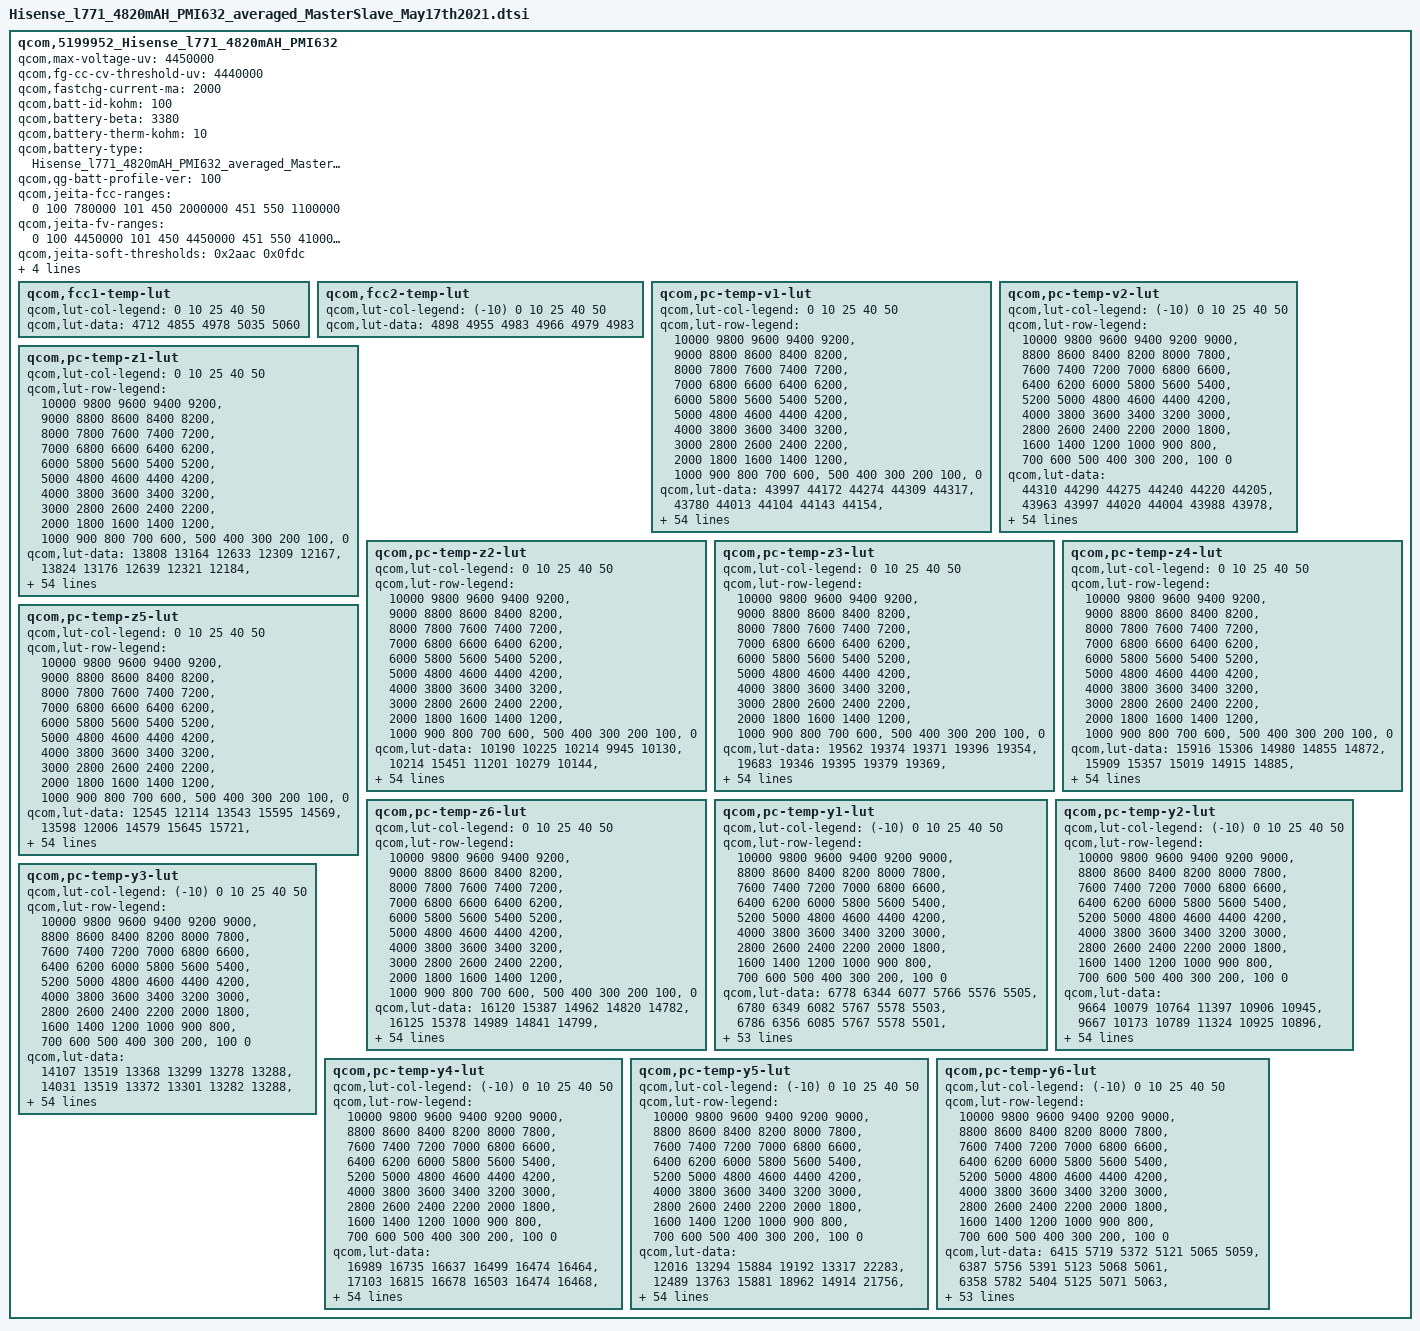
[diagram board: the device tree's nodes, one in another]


qcom,5199952_Hisense_l771_4820mAH_PMI632 {
    /* 5199952_Hisense_l771_4820mAH_PMI632_averaged_MasterSlave_May17th2021 */
    qcom,max-voltage-uv = <4450000>;
    qcom,fg-cc-cv-threshold-uv = <4440000>;
    qcom,fastchg-current-ma = <2000>;
    qcom,batt-id-kohm = <100>;
    qcom,battery-beta = <3380>;
    qcom,battery-therm-kohm = <10>;
    qcom,battery-type = "Hisense_l771_4820mAH_PMI632_averaged_MasterSlave_May17th2021";
    qcom,qg-batt-profile-ver = <100>;

	qcom,jeita-fcc-ranges = <0  100  780000
				101 450  2000000
				451 550  1100000>;

	qcom,jeita-fv-ranges =  <0  100  4450000
				 101 450  4450000
				 451 550  4100000>;
	/* COOL = 10 DegC, WARM = 45 DegC */
	qcom,jeita-soft-thresholds = <0x2aac 0x0fdc>;
	/* COLD = 0 DegC, HOT = 53 DegC */
	qcom,jeita-hard-thresholds = <0x36b9 0x0ca0>;
	/* COOL hys = 13 degC, WARM hys = 42 degC */
	qcom,jeita-soft-hys-thresholds = <0x2767 0x1149>;
	qcom,jeita-soft-fcc-ua = <780000 1100000>;
	qcom,jeita-soft-fv-uv = <4450000 4100000>;

	qcom,fcc1-temp-lut {
		qcom,lut-col-legend = <0 10 25 40 50>;
		qcom,lut-data = <4712 4855 4978 5035 5060>;
	};

	qcom,fcc2-temp-lut {
		qcom,lut-col-legend = <(-10) 0 10 25 40 50>;
		qcom,lut-data = <4898 4955 4983 4966 4979 4983>;
	};

	qcom,pc-temp-v1-lut {
		qcom,lut-col-legend = <0 10 25 40 50>;
		qcom,lut-row-legend = <10000 9800 9600 9400 9200>,
			<9000 8800 8600 8400 8200>,
			<8000 7800 7600 7400 7200>,
			<7000 6800 6600 6400 6200>,
			<6000 5800 5600 5400 5200>,
			<5000 4800 4600 4400 4200>,
			<4000 3800 3600 3400 3200>,
			<3000 2800 2600 2400 2200>,
			<2000 1800 1600 1400 1200>,
			<1000 900 800 700 600>,
			<500 400 300 200 100>,
			<0>;
		qcom,lut-data = <43997 44172 44274 44309 44317>,
			<43780 44013 44104 44143 44154>,
			<43555 43788 43926 43973 43987>,
			<43324 43555 43735 43781 43801>,
			<43090 43328 43529 43577 43601>,
			<42850 43095 43297 43361 43389>,
			<42606 42855 43049 43131 43163>,
			<42367 42610 42803 42893 42926>,
			<42129 42365 42557 42651 42685>,
			<41895 42123 42311 42404 42436>,
			<41668 41884 42067 42159 42190>,
			<41447 41651 41826 41915 41945>,
			<41227 41422 41590 41675 41704>,
			<41009 41200 41357 41438 41466>,
			<40796 40982 41135 41208 41234>,
			<40592 40771 40926 40984 41011>,
			<40395 40566 40721 40767 40795>,
			<40207 40368 40515 40563 40588>,
			<40027 40178 40313 40375 40390>,
			<39855 39999 40117 40181 40192>,
			<39695 39822 39935 39975 39987>,
			<39545 39638 39728 39758 39776>,
			<39397 39451 39422 39509 39544>,
			<39250 39247 39114 39238 39285>,
			<39104 38998 38962 39050 39088>,
			<38956 38785 38873 38936 38964>,
			<38802 38673 38787 38837 38860>,
			<38671 38595 38693 38732 38751>,
			<38570 38523 38602 38633 38646>,
			<38486 38457 38516 38537 38543>,
			<38420 38397 38437 38446 38442>,
			<38368 38342 38363 38360 38349>,
			<38323 38291 38297 38282 38269>,
			<38283 38244 38234 38207 38195>,
			<38247 38202 38176 38135 38120>,
			<38210 38160 38120 38065 38047>,
			<38174 38116 38063 37999 37974>,
			<38133 38070 38008 37939 37903>,
			<38072 38007 37941 37870 37824>,
			<37988 37915 37847 37772 37719>,
			<37888 37807 37735 37653 37593>,
			<37762 37682 37614 37529 37464>,
			<37619 37539 37478 37396 37330>,
			<37454 37377 37323 37246 37183>,
			<37327 37237 37179 37110 37050>,
			<37223 37148 37087 37024 36973>,
			<37173 37121 37058 36996 36941>,
			<37139 37088 37039 36975 36919>,
			<37100 37058 37014 36953 36894>,
			<37041 36996 36952 36886 36817>,
			<36847 36752 36709 36622 36532>,
			<36405 36301 36269 36178 36080>,
			<35825 35705 35686 35596 35505>,
			<35031 34882 34891 34809 34718>,
			<33700 33497 33660 33599 33502>,
			<30000 30000 30000 30000 30000>;
	};

	qcom,pc-temp-v2-lut {
		qcom,lut-col-legend = <(-10) 0 10 25 40 50>;
		qcom,lut-row-legend = <10000 9800 9600 9400 9200 9000>,
			<8800 8600 8400 8200 8000 7800>,
			<7600 7400 7200 7000 6800 6600>,
			<6400 6200 6000 5800 5600 5400>,
			<5200 5000 4800 4600 4400 4200>,
			<4000 3800 3600 3400 3200 3000>,
			<2800 2600 2400 2200 2000 1800>,
			<1600 1400 1200 1000 900 800>,
			<700 600 500 400 300 200>,
			<100 0>;
		qcom,lut-data = <44310 44290 44275 44240 44220 44205>,
			<43963 43997 44020 44004 43988 43978>,
			<43643 43726 43776 43773 43762 43755>,
			<43352 43482 43546 43551 43546 43538>,
			<43089 43263 43329 43337 43337 43328>,
			<42835 43036 43102 43114 43120 43111>,
			<42586 42791 42860 42878 42887 42880>,
			<42344 42539 42611 42635 42646 42642>,
			<42099 42286 42361 42391 42404 42401>,
			<41853 42030 42108 42144 42157 42155>,
			<41611 41779 41860 41901 41914 41912>,
			<41372 41531 41617 41660 41673 41671>,
			<41139 41295 41380 41424 41436 41433>,
			<40920 41089 41152 41194 41203 41200>,
			<40711 40897 40932 40969 40976 40974>,
			<40468 40684 40724 40751 40757 40755>,
			<40147 40449 40529 40538 40546 40545>,
			<39829 40199 40314 40333 40342 40341>,
			<39590 39928 40043 40148 40155 40153>,
			<39386 39651 39758 39962 39964 39962>,
			<39187 39396 39513 39725 39729 39729>,
			<38985 39156 39290 39433 39454 39460>,
			<38798 38941 39091 39185 39217 39228>,
			<38630 38755 38913 38997 39027 39037>,
			<38478 38587 38753 38837 38863 38872>,
			<38362 38426 38611 38696 38721 38729>,
			<38274 38275 38483 38573 38598 38604>,
			<38196 38168 38357 38459 38485 38488>,
			<38123 38098 38228 38351 38379 38381>,
			<38055 38039 38114 38251 38282 38282>,
			<37988 37980 38017 38162 38198 38195>,
			<37921 37924 37932 38080 38121 38113>,
			<37855 37868 37868 38005 38041 38033>,
			<37786 37812 37817 37937 37959 37953>,
			<37715 37756 37769 37868 37874 37865>,
			<37642 37697 37721 37793 37787 37763>,
			<37566 37635 37670 37715 37696 37656>,
			<37489 37566 37608 37634 37601 37552>,
			<37408 37492 37532 37549 37502 37451>,
			<37327 37409 37446 37463 37406 37353>,
			<37250 37314 37342 37377 37317 37262>,
			<37176 37208 37225 37274 37212 37156>,
			<37110 37089 37090 37139 37081 37031>,
			<37043 36961 36947 37013 36958 36903>,
			<36971 36849 36824 36895 36867 36818>,
			<36882 36761 36735 36843 36826 36779>,
			<36831 36726 36699 36827 36814 36767>,
			<36779 36693 36655 36811 36797 36751>,
			<36717 36646 36585 36778 36765 36715>,
			<36639 36563 36467 36700 36671 36595>,
			<36520 36355 36206 36412 36329 36222>,
			<36304 35919 35747 35919 35824 35711>,
			<35904 35236 35094 35286 35170 35044>,
			<35266 34271 34157 34430 34267 34122>,
			<34215 32940 32742 33163 33019 32859>,
			<33190 29783 27667 27737 27880 27908>;
	};

	qcom,pc-temp-z1-lut {
		qcom,lut-col-legend = <0 10 25 40 50>;
		qcom,lut-row-legend = <10000 9800 9600 9400 9200>,
			<9000 8800 8600 8400 8200>,
			<8000 7800 7600 7400 7200>,
			<7000 6800 6600 6400 6200>,
			<6000 5800 5600 5400 5200>,
			<5000 4800 4600 4400 4200>,
			<4000 3800 3600 3400 3200>,
			<3000 2800 2600 2400 2200>,
			<2000 1800 1600 1400 1200>,
			<1000 900 800 700 600>,
			<500 400 300 200 100>,
			<0>;
		qcom,lut-data = <13808 13164 12633 12309 12167>,
			<13824 13176 12639 12321 12184>,
			<13822 13186 12641 12314 12184>,
			<13804 13190 12641 12312 12179>,
			<13788 13182 12639 12307 12176>,
			<13778 13169 12633 12302 12173>,
			<13768 13156 12622 12296 12170>,
			<13762 13140 12613 12290 12166>,
			<13758 13125 12601 12283 12162>,
			<13756 13112 12589 12277 12158>,
			<13748 13099 12581 12272 12157>,
			<13729 13088 12574 12269 12157>,
			<13716 13080 12569 12266 12156>,
			<13695 13071 12565 12265 12156>,
			<13674 13060 12562 12264 12155>,
			<13660 13050 12562 12263 12155>,
			<13648 13047 12562 12262 12156>,
			<13643 13045 12559 12261 12156>,
			<13648 13044 12555 12261 12155>,
			<13653 13048 12555 12261 12154>,
			<13648 13053 12556 12261 12155>,
			<13633 13054 12557 12260 12155>,
			<13624 13057 12561 12260 12156>,
			<13622 13058 12566 12260 12156>,
			<13621 13066 12568 12260 12157>,
			<13627 13072 12569 12262 12158>,
			<13655 13071 12569 12265 12159>,
			<13675 13067 12572 12268 12162>,
			<13671 13067 12575 12271 12164>,
			<13663 13078 12582 12274 12168>,
			<13661 13088 12591 12278 12172>,
			<13663 13092 12594 12282 12176>,
			<13664 13095 12595 12287 12180>,
			<13659 13098 12596 12293 12184>,
			<13650 13101 12599 12298 12188>,
			<13652 13105 12605 12303 12193>,
			<13676 13115 12612 12308 12198>,
			<13700 13129 12622 12312 12203>,
			<13712 13136 12628 12316 12207>,
			<13729 13138 12632 12321 12211>,
			<13743 13142 12636 12325 12214>,
			<13759 13148 12641 12328 12216>,
			<13773 13158 12647 12332 12219>,
			<13769 13172 12654 12335 12221>,
			<13772 13182 12662 12340 12224>,
			<13762 13193 12665 12344 12226>,
			<13758 13196 12666 12343 12225>,
			<13757 13191 12669 12345 12226>,
			<13786 13177 12679 12349 12229>,
			<13766 13191 12678 12352 12233>,
			<13799 13228 12679 12358 12238>,
			<13823 13227 12694 12369 12244>,
			<13809 13239 12702 12377 12254>,
			<13840 13263 12727 12394 12270>,
			<13840 13263 12727 12394 12270>,
			<13840 13263 12727 12394 12270>;
	};

	qcom,pc-temp-z2-lut {
		qcom,lut-col-legend = <0 10 25 40 50>;
		qcom,lut-row-legend = <10000 9800 9600 9400 9200>,
			<9000 8800 8600 8400 8200>,
			<8000 7800 7600 7400 7200>,
			<7000 6800 6600 6400 6200>,
			<6000 5800 5600 5400 5200>,
			<5000 4800 4600 4400 4200>,
			<4000 3800 3600 3400 3200>,
			<3000 2800 2600 2400 2200>,
			<2000 1800 1600 1400 1200>,
			<1000 900 800 700 600>,
			<500 400 300 200 100>,
			<0>;
		qcom,lut-data = <10190 10225 10214 9945 10130>,
			<10214 15451 11201 10279 10144>,
			<10217 12170 11731 10297 10109>,
			<10211 10433 11796 10327 10208>,
			<10203 10387 11702 10333 10258>,
			<10187 10362 11166 10333 10272>,
			<10167 10333 10525 10322 10247>,
			<10157 10306 10381 10306 10219>,
			<10151 10284 10355 10277 10212>,
			<10148 10264 10335 10240 10208>,
			<10194 10250 10311 10211 10198>,
			<10286 10245 10294 10186 10171>,
			<10306 10244 10288 10179 10157>,
			<10208 10245 10286 10194 10159>,
			<10116 10248 10317 10212 10163>,
			<10108 10253 10711 10218 10167>,
			<10107 10265 11060 10222 10174>,
			<10107 10289 10865 10302 10179>,
			<10112 10311 10457 10749 10182>,
			<10120 10331 10362 11015 10187>,
			<10131 10349 10386 10787 10248>,
			<10146 10365 10409 10466 10343>,
			<10162 10381 10422 10356 10321>,
			<10181 10384 10431 10261 10157>,
			<10201 10364 10419 10202 10078>,
			<10216 10346 10370 10162 10095>,
			<10228 10351 10348 10144 10120>,
			<10238 10366 10365 10163 10137>,
			<10246 10376 10391 10208 10155>,
			<10252 10382 10413 10257 10204>,
			<10260 10388 10434 10337 10367>,
			<10268 10395 10440 10380 10466>,
			<10276 10403 10437 10382 10412>,
			<10285 10412 10436 10378 10311>,
			<10294 10420 10437 10359 10211>,
			<10304 10429 10441 10323 10102>,
			<10314 10438 10448 10312 10070>,
			<10326 10448 10468 10319 10103>,
			<10338 10461 10491 10331 10148>,
			<10353 10478 10525 10380 10179>,
			<10369 10493 10556 10451 10213>,
			<10387 10503 10566 10475 10284>,
			<10414 10513 10571 10488 10409>,
			<10470 10535 10573 10486 10421>,
			<10271 10649 10599 10463 10381>,
			<9638 10791 10662 10363 10247>,
			<9952 10587 10651 10320 10219>,
			<9795 10608 10630 10315 10220>,
			<9590 10626 10626 10351 10263>,
			<9608 10610 10686 10449 10335>,
			<9558 10525 10674 10379 10249>,
			<9647 10389 10546 10197 10055>,
			<9731 10234 10491 10135 9988>,
			<9660 10078 10403 10080 9931>,
			<9660 10078 10403 10080 9931>,
			<9660 10078 10403 10080 9931>;
	};

	qcom,pc-temp-z3-lut {
		qcom,lut-col-legend = <0 10 25 40 50>;
		qcom,lut-row-legend = <10000 9800 9600 9400 9200>,
			<9000 8800 8600 8400 8200>,
			<8000 7800 7600 7400 7200>,
			<7000 6800 6600 6400 6200>,
			<6000 5800 5600 5400 5200>,
			<5000 4800 4600 4400 4200>,
			<4000 3800 3600 3400 3200>,
			<3000 2800 2600 2400 2200>,
			<2000 1800 1600 1400 1200>,
			<1000 900 800 700 600>,
			<500 400 300 200 100>,
			<0>;
		qcom,lut-data = <19562 19374 19371 19396 19354>,
			<19683 19346 19395 19379 19369>,
			<19747 19497 19412 19389 19371>,
			<19789 19585 19429 19415 19403>,
			<19810 19598 19445 19429 19416>,
			<19817 19606 19465 19440 19426>,
			<19822 19611 19487 19451 19435>,
			<19821 19616 19493 19456 19441>,
			<19807 19617 19495 19456 19446>,
			<19797 19614 19496 19456 19450>,
			<19811 19609 19495 19455 19451>,
			<19840 19603 19492 19453 19449>,
			<19846 19595 19488 19450 19447>,
			<19812 19591 19481 19446 19442>,
			<19779 19589 19479 19440 19435>,
			<19772 19587 19490 19435 19428>,
			<19769 19583 19500 19430 19420>,
			<19767 19575 19485 19426 19413>,
			<19766 19569 19456 19424 19406>,
			<19765 19565 19449 19424 19402>,
			<19762 19563 19452 19423 19402>,
			<19758 19567 19456 19420 19402>,
			<19756 19577 19463 19414 19399>,
			<19757 19586 19471 19406 19386>,
			<19758 19594 19468 19396 19374>,
			<19761 19599 19452 19383 19363>,
			<19768 19596 19442 19375 19356>,
			<19771 19589 19439 19376 19359>,
			<19768 19583 19437 19377 19369>,
			<19760 19578 19439 19382 19385>,
			<19752 19574 19444 19397 19418>,
			<19742 19571 19449 19411 19437>,
			<19732 19568 19455 19420 19433>,
			<19722 19567 19458 19426 19425>,
			<19713 19566 19458 19425 19415>,
			<19704 19564 19458 19418 19401>,
			<19695 19562 19457 19410 19390>,
			<19687 19559 19451 19398 19381>,
			<19681 19556 19446 19391 19377>,
			<19677 19552 19445 19391 19375>,
			<19670 19547 19444 19392 19375>,
			<19658 19543 19441 19393 19377>,
			<19641 19537 19437 19395 19388>,
			<19619 19527 19432 19396 19392>,
			<19440 19495 19423 19393 19392>,
			<19286 19436 19405 19372 19365>,
			<19328 19346 19403 19367 19358>,
			<19295 19335 19392 19362 19349>,
			<19279 19308 19389 19352 19341>,
			<19275 19306 19377 19344 19339>,
			<19282 19330 19368 19362 19370>,
			<19314 19331 19359 19384 19391>,
			<19350 19331 19361 19390 19388>,
			<19383 19347 19355 19389 19385>,
			<19383 19347 19355 19389 19385>,
			<19383 19347 19355 19389 19385>;
	};

	qcom,pc-temp-z4-lut {
		qcom,lut-col-legend = <0 10 25 40 50>;
		qcom,lut-row-legend = <10000 9800 9600 9400 9200>,
			<9000 8800 8600 8400 8200>,
			<8000 7800 7600 7400 7200>,
			<7000 6800 6600 6400 6200>,
			<6000 5800 5600 5400 5200>,
			<5000 4800 4600 4400 4200>,
			<4000 3800 3600 3400 3200>,
			<3000 2800 2600 2400 2200>,
			<2000 1800 1600 1400 1200>,
			<1000 900 800 700 600>,
			<500 400 300 200 100>,
			<0>;
		qcom,lut-data = <15916 15306 14980 14855 14872>,
			<15909 15357 15019 14915 14885>,
			<15863 15317 15076 14930 14872>,
			<15697 15264 15019 14935 14912>,
			<15529 15187 14958 14905 14890>,
			<15414 15099 14924 14877 14866>,
			<15313 15033 14897 14849 14844>,
			<15234 14976 14868 14823 14823>,
			<15175 14931 14837 14802 14803>,
			<15115 14896 14810 14784 14784>,
			<15023 14867 14787 14766 14766>,
			<14925 14843 14768 14749 14748>,
			<14899 14823 14753 14735 14735>,
			<14907 14805 14741 14723 14726>,
			<14916 14785 14723 14713 14720>,
			<14908 14769 14684 14708 14715>,
			<14886 14759 14656 14704 14712>,
			<14864 14751 14671 14697 14708>,
			<14846 14745 14703 14678 14703>,
			<14829 14740 14711 14668 14700>,
			<14814 14736 14710 14681 14706>,
			<14801 14737 14710 14708 14723>,
			<14791 14740 14776 14759 14759>,
			<14780 14748 14869 14845 14840>,
			<14773 14803 14879 14873 14876>,
			<14775 14852 14869 14870 14873>,
			<14790 14850 14857 14863 14865>,
			<14802 14837 14843 14852 14852>,
			<14806 14824 14827 14834 14827>,
			<14809 14810 14809 14811 14795>,
			<14809 14797 14789 14779 14745>,
			<14803 14784 14770 14751 14712>,
			<14796 14771 14751 14725 14702>,
			<14788 14760 14736 14706 14696>,
			<14779 14748 14725 14703 14696>,
			<14772 14740 14717 14701 14699>,
			<14765 14735 14716 14701 14700>,
			<14759 14731 14717 14702 14699>,
			<14751 14731 14718 14703 14699>,
			<14743 14733 14723 14710 14708>,
			<14740 14735 14729 14721 14725>,
			<14740 14732 14729 14722 14726>,
			<14740 14726 14726 14718 14715>,
			<14733 14720 14722 14716 14711>,
			<14833 14703 14706 14710 14706>,
			<14962 14703 14677 14686 14687>,
			<14914 14796 14669 14684 14687>,
			<14940 14803 14663 14673 14679>,
			<14954 14824 14653 14661 14660>,
			<14951 14821 14659 14660 14649>,
			<14952 14809 14692 14677 14666>,
			<14945 14827 14716 14678 14675>,
			<14933 14841 14719 14679 14686>,
			<14941 14847 14731 14687 14697>,
			<14941 14847 14731 14687 14697>,
			<14941 14847 14731 14687 14697>;
	};

	qcom,pc-temp-z5-lut {
		qcom,lut-col-legend = <0 10 25 40 50>;
		qcom,lut-row-legend = <10000 9800 9600 9400 9200>,
			<9000 8800 8600 8400 8200>,
			<8000 7800 7600 7400 7200>,
			<7000 6800 6600 6400 6200>,
			<6000 5800 5600 5400 5200>,
			<5000 4800 4600 4400 4200>,
			<4000 3800 3600 3400 3200>,
			<3000 2800 2600 2400 2200>,
			<2000 1800 1600 1400 1200>,
			<1000 900 800 700 600>,
			<500 400 300 200 100>,
			<0>;
		qcom,lut-data = <12545 12114 13543 15595 14569>,
			<13598 12006 14579 15645 15721>,
			<14269 14294 14693 15780 15835>,
			<14736 15811 14695 16919 17167>,
			<15116 16196 14912 17757 18076>,
			<15467 16483 16049 18634 18953>,
			<15764 16939 17690 19566 19825>,
			<15967 17539 18629 20364 20759>,
			<16083 18072 19202 20941 21915>,
			<16249 18498 19804 21477 23241>,
			<17270 18894 20552 22149 24540>,
			<18988 19278 21340 22973 25840>,
			<19457 19653 22026 23956 27047>,
			<18883 20141 22692 25267 28363>,
			<18350 21208 24197 26558 29330>,
			<18527 22473 30523 27546 29339>,
			<19209 23371 35715 28388 29110>,
			<20026 24186 32695 29540 29064>,
			<21075 25046 26397 32769 29632>,
			<22316 25865 25268 34610 30549>,
			<23515 27026 28157 36208 32259>,
			<24743 30529 31754 37621 34212>,
			<26472 37322 36313 35047 33106>,
			<29808 42546 40442 29023 26466>,
			<34285 46665 38603 24191 21214>,
			<39237 49090 29519 20348 18189>,
			<45528 46654 23888 17944 16466>,
			<48791 40059 22042 17185 16442>,
			<47836 35785 21106 16753 16621>,
			<45752 33242 21284 16940 17717>,
			<43611 31794 22059 18452 23832>,
			<40982 31690 23147 20559 28638>,
			<38689 32065 25113 24211 30053>,
			<37151 32748 27505 27859 30855>,
			<35818 34679 30606 29414 30258>,
			<34846 36548 33610 30423 27958>,
			<33621 37642 34055 30418 26550>,
			<32755 38666 33692 28211 25997>,
			<33536 39051 33421 26525 25599>,
			<35641 39172 33300 26815 25190>,
			<36416 39011 33112 27300 24860>,
			<34491 38122 31796 26881 24938>,
			<32245 36759 29039 25180 25700>,
			<30810 35706 28591 25390 27095>,
			<18383 33067 29187 25688 27926>,
			<11845 22713 29511 22719 21175>,
			<12433 13879 29183 21044 19157>,
			<11897 13317 25867 21149 18173>,
			<11634 12425 26277 20669 19039>,
			<11610 12430 22993 19107 20043>,
			<11687 13201 18521 20284 25196>,
			<12080 12902 15843 21117 24818>,
			<12350 12638 15490 20886 20631>,
			<12779 12756 14652 18723 17603>,
			<12779 12756 14652 18723 17603>,
			<12779 12756 14652 18723 17603>;
	};

	qcom,pc-temp-z6-lut {
		qcom,lut-col-legend = <0 10 25 40 50>;
		qcom,lut-row-legend = <10000 9800 9600 9400 9200>,
			<9000 8800 8600 8400 8200>,
			<8000 7800 7600 7400 7200>,
			<7000 6800 6600 6400 6200>,
			<6000 5800 5600 5400 5200>,
			<5000 4800 4600 4400 4200>,
			<4000 3800 3600 3400 3200>,
			<3000 2800 2600 2400 2200>,
			<2000 1800 1600 1400 1200>,
			<1000 900 800 700 600>,
			<500 400 300 200 100>,
			<0>;
		qcom,lut-data = <16120 15387 14962 14820 14782>,
			<16125 15378 14989 14841 14799>,
			<16107 15402 15018 14854 14794>,
			<16016 15413 14997 14863 14824>,
			<15919 15375 14977 14860 14823>,
			<15848 15314 14968 14855 14822>,
			<15783 15271 14960 14847 14817>,
			<15725 15235 14949 14838 14810>,
			<15672 15204 14933 14829 14804>,
			<15625 15177 14917 14819 14798>,
			<15584 15153 14904 14811 14791>,
			<15546 15132 14891 14802 14783>,
			<15517 15113 14880 14794 14776>,
			<15493 15096 14869 14785 14769>,
			<15473 15082 14860 14778 14762>,
			<15455 15069 14851 14773 14756>,
			<15438 15059 14844 14768 14750>,
			<15423 15050 14840 14762 14744>,
			<15408 15044 14837 14753 14738>,
			<15395 15040 14836 14750 14734>,
			<15384 15038 14838 14754 14736>,
			<15374 15040 14840 14762 14743>,
			<15368 15047 14872 14780 14756>,
			<15365 15058 14917 14811 14783>,
			<15363 15087 14920 14821 14794>,
			<15366 15111 14908 14814 14789>,
			<15378 15109 14898 14806 14781>,
			<15386 15102 14891 14800 14776>,
			<15386 15095 14885 14795 14772>,
			<15385 15089 14880 14790 14768>,
			<15383 15082 14875 14785 14765>,
			<15378 15077 14871 14780 14761>,
			<15371 15072 14867 14776 14756>,
			<15364 15068 14863 14772 14750>,
			<15357 15064 14861 14769 14744>,
			<15353 15061 14859 14766 14739>,
			<15352 15062 14858 14762 14734>,
			<15351 15062 14857 14757 14729>,
			<15352 15063 14856 14754 14726>,
			<15356 15067 14859 14757 14729>,
			<15359 15071 14864 14762 14736>,
			<15364 15072 14864 14764 14738>,
			<15366 15072 14863 14764 14740>,
			<15364 15071 14861 14764 14740>,
			<15333 15058 14854 14761 14739>,
			<15316 15035 14836 14741 14716>,
			<15315 15028 14832 14737 14713>,
			<15312 15026 14824 14730 14705>,
			<15312 15023 14818 14719 14692>,
			<15317 15026 14818 14716 14687>,
			<15329 15039 14831 14734 14711>,
			<15349 15054 14841 14749 14730>,
			<15371 15069 14849 14755 14736>,
			<15413 15095 14858 14763 14743>,
			<15413 15095 14858 14763 14743>,
			<15413 15095 14858 14763 14743>;
	};

	qcom,pc-temp-y1-lut {
		qcom,lut-col-legend = <(-10) 0 10 25 40 50>;
		qcom,lut-row-legend = <10000 9800 9600 9400 9200 9000>,
			<8800 8600 8400 8200 8000 7800>,
			<7600 7400 7200 7000 6800 6600>,
			<6400 6200 6000 5800 5600 5400>,
			<5200 5000 4800 4600 4400 4200>,
			<4000 3800 3600 3400 3200 3000>,
			<2800 2600 2400 2200 2000 1800>,
			<1600 1400 1200 1000 900 800>,
			<700 600 500 400 300 200>,
			<100 0>;
		qcom,lut-data = <6778 6344 6077 5766 5576 5505>,
			<6780 6349 6082 5767 5578 5503>,
			<6786 6356 6085 5767 5578 5501>,
			<6795 6363 6086 5767 5578 5499>,
			<6803 6369 6085 5767 5578 5498>,
			<6808 6372 6084 5767 5577 5497>,
			<6820 6383 6075 5767 5575 5497>,
			<6835 6395 6066 5767 5573 5497>,
			<6836 6392 6065 5765 5572 5496>,
			<6833 6380 6065 5760 5570 5495>,
			<6830 6374 6065 5759 5568 5493>,
			<6829 6371 6064 5760 5566 5493>,
			<6826 6369 6064 5762 5564 5492>,
			<6822 6375 6068 5760 5564 5492>,
			<6816 6384 6074 5756 5564 5491>,
			<6818 6386 6075 5755 5563 5491>,
			<6833 6380 6071 5754 5562 5490>,
			<6845 6377 6068 5754 5561 5489>,
			<6837 6388 6074 5754 5561 5489>,
			<6816 6405 6082 5755 5560 5488>,
			<6811 6409 6083 5755 5561 5488>,
			<6829 6401 6080 5755 5561 5488>,
			<6846 6396 6078 5755 5562 5488>,
			<6844 6392 6074 5758 5563 5490>,
			<6837 6387 6069 5763 5565 5491>,
			<6833 6386 6074 5765 5566 5493>,
			<6824 6392 6083 5766 5568 5495>,
			<6816 6393 6085 5767 5570 5496>,
			<6810 6390 6082 5769 5572 5499>,
			<6803 6388 6079 5772 5574 5501>,
			<6802 6386 6079 5777 5577 5503>,
			<6807 6385 6079 5783 5580 5505>,
			<6810 6386 6083 5784 5583 5507>,
			<6813 6390 6093 5783 5586 5509>,
			<6817 6392 6097 5783 5588 5510>,
			<6817 6382 6086 5783 5589 5512>,
			<6812 6364 6073 5785 5589 5513>,
			<6808 6360 6074 5787 5590 5514>,
			<6797 6360 6079 5788 5592 5515>,
			<6782 6361 6080 5791 5593 5516>,
			<6775 6374 6073 5796 5594 5517>,
			<6764 6381 6074 5798 5594 5518>,
			<6763 6361 6086 5794 5597 5519>,
			<6768 6362 6080 5803 5602 5524>,
			<6839 6402 6092 5806 5607 5528>,
			<6831 6399 6087 5805 5607 5528>,
			<6826 6402 6101 5809 5607 5528>,
			<6827 6404 6093 5811 5608 5528>,
			<6855 6402 6090 5811 5605 5528>,
			<6840 6401 6096 5813 5606 5529>,
			<6875 6409 6110 5812 5608 5533>,
			<6936 6445 6111 5824 5614 5539>,
			<7022 6510 6138 5837 5624 5546>,
			<7182 6662 6193 5861 5637 5557>,
			<7182 6662 6193 5861 5637 5557>,
			<7182 6662 6193 5861 5637 5557>;
	};

	qcom,pc-temp-y2-lut {
		qcom,lut-col-legend = <(-10) 0 10 25 40 50>;
		qcom,lut-row-legend = <10000 9800 9600 9400 9200 9000>,
			<8800 8600 8400 8200 8000 7800>,
			<7600 7400 7200 7000 6800 6600>,
			<6400 6200 6000 5800 5600 5400>,
			<5200 5000 4800 4600 4400 4200>,
			<4000 3800 3600 3400 3200 3000>,
			<2800 2600 2400 2200 2000 1800>,
			<1600 1400 1200 1000 900 800>,
			<700 600 500 400 300 200>,
			<100 0>;
		qcom,lut-data = <9664 10079 10764 11397 10906 10945>,
			<9667 10173 10789 11324 10925 10896>,
			<9670 10274 10828 11246 10934 10830>,
			<9672 10370 10870 11171 10935 10761>,
			<9675 10449 10901 11110 10931 10707>,
			<9678 10500 10911 11070 10924 10684>,
			<9680 10533 10907 11048 10897 10680>,
			<9683 10553 10903 11031 10863 10679>,
			<9685 10559 10904 11011 10842 10672>,
			<9688 10562 10906 10992 10825 10661>,
			<9688 10575 10911 10987 10816 10645>,
			<9687 10680 10923 11000 10809 10615>,
			<9685 10785 10944 11014 10805 10595>,
			<9685 10808 10987 11021 10811 10625>,
			<9685 10821 11056 11027 10825 10689>,
			<9685 10848 11131 11047 10842 10730>,
			<9681 10912 11224 11114 10876 10756>,
			<9678 10951 11267 11191 10921 10792>,
			<9676 10938 11249 11272 11009 10888>,
			<9675 10902 11224 11340 11099 10987>,
			<9674 10723 11220 11339 11126 11005>,
			<9674 10119 11220 11308 11139 11004>,
			<9673 9783 11221 11293 11141 10995>,
			<9672 9753 11221 11312 11114 10952>,
			<9671 9735 11220 11340 11088 10915>,
			<9670 9715 11216 11362 11123 10951>,
			<9670 9695 11208 11385 11206 11034>,
			<9669 9686 11188 11404 11236 11063>,
			<9668 9683 11122 11419 11240 11068>,
			<9667 9680 11054 11434 11246 11075>,
			<9666 9677 11014 11452 11290 11132>,
			<9666 9673 10979 11471 11356 11231>,
			<9666 9671 10929 11476 11377 11311>,
			<9665 9669 10863 11475 11379 11388>,
			<9665 9667 10779 11470 11378 11415>,
			<9665 9666 10592 11447 11374 11342>,
			<9664 9665 10370 11409 11362 11245>,
			<9664 9664 10152 11365 11325 11202>,
			<9664 9663 9859 11310 11252 11171>,
			<9664 9663 9739 11280 11221 11142>,
			<9664 9663 9708 11273 11222 11113>,
			<9664 9663 9692 11255 11213 11085>,
			<9664 9662 9682 11169 11162 11036>,
			<9663 9661 9676 11146 11034 10899>,
			<9662 9661 9676 11112 10937 10779>,
			<9661 9660 9668 11055 10931 10759>,
			<9661 9660 9666 11038 10943 10830>,
			<9660 9659 9664 11067 10978 10859>,
			<9659 9659 9662 11063 11016 10889>,
			<9657 9658 9660 11085 11032 10878>,
			<9654 9656 9658 11003 10945 10720>,
			<9652 9653 9657 10903 10855 10643>,
			<9650 9651 9656 10803 10764 10577>,
			<9649 9650 9653 10704 10671 10506>,
			<9649 9650 9653 10704 10671 10506>,
			<9649 9650 9653 10704 10671 10506>;
	};

	qcom,pc-temp-y3-lut {
		qcom,lut-col-legend = <(-10) 0 10 25 40 50>;
		qcom,lut-row-legend = <10000 9800 9600 9400 9200 9000>,
			<8800 8600 8400 8200 8000 7800>,
			<7600 7400 7200 7000 6800 6600>,
			<6400 6200 6000 5800 5600 5400>,
			<5200 5000 4800 4600 4400 4200>,
			<4000 3800 3600 3400 3200 3000>,
			<2800 2600 2400 2200 2000 1800>,
			<1600 1400 1200 1000 900 800>,
			<700 600 500 400 300 200>,
			<100 0>;
		qcom,lut-data = <14107 13519 13368 13299 13278 13288>,
			<14031 13519 13372 13301 13282 13288>,
			<13955 13519 13376 13303 13286 13288>,
			<13884 13518 13380 13305 13290 13289>,
			<13824 13517 13384 13306 13293 13290>,
			<13779 13516 13386 13308 13296 13291>,
			<13750 13514 13388 13309 13297 13292>,
			<13727 13512 13389 13310 13298 13294>,
			<13702 13507 13390 13311 13298 13295>,
			<13677 13498 13390 13312 13299 13295>,
			<13654 13489 13389 13312 13299 13295>,
			<13629 13481 13386 13314 13300 13296>,
			<13611 13472 13382 13315 13301 13296>,
			<13609 13460 13377 13316 13301 13296>,
			<13610 13447 13373 13318 13301 13297>,
			<13609 13443 13371 13318 13302 13299>,
			<13588 13442 13371 13315 13305 13303>,
			<13565 13441 13370 13313 13307 13305>,
			<13558 13429 13364 13314 13306 13304>,
			<13554 13411 13355 13316 13303 13302>,
			<13554 13404 13349 13315 13300 13299>,
			<13554 13400 13344 13308 13296 13293>,
			<13555 13398 13340 13304 13293 13290>,
			<13556 13402 13337 13302 13291 13289>,
			<13557 13407 13335 13300 13290 13288>,
			<13562 13403 13333 13300 13290 13288>,
			<13579 13390 13331 13299 13289 13289>,
			<13603 13386 13330 13299 13289 13288>,
			<13631 13405 13329 13298 13287 13286>,
			<13666 13433 13328 13297 13286 13284>,
			<13700 13458 13327 13297 13287 13284>,
			<13736 13487 13325 13297 13288 13285>,
			<13771 13521 13325 13297 13289 13285>,
			<13808 13563 13328 13298 13288 13287>,
			<13845 13609 13331 13299 13288 13288>,
			<13879 13655 13337 13299 13289 13287>,
			<13912 13702 13344 13299 13289 13287>,
			<13942 13747 13356 13299 13289 13287>,
			<13969 13790 13375 13298 13289 13287>,
			<13995 13827 13393 13298 13289 13288>,
			<14017 13858 13411 13301 13291 13290>,
			<14037 13888 13432 13303 13291 13290>,
			<14068 13923 13458 13301 13289 13288>,
			<14111 13955 13481 13301 13285 13285>,
			<14147 13957 13479 13297 13286 13287>,
			<14209 14050 13565 13303 13296 13296>,
			<14281 14110 13629 13308 13299 13298>,
			<14383 14182 13713 13314 13302 13301>,
			<14520 14277 13821 13318 13304 13302>,
			<14773 14428 13979 13321 13303 13299>,
			<15562 14745 14132 13315 13298 13294>,
			<18103 16017 14321 13315 13298 13295>,
			<26303 21543 14759 13325 13302 13302>,
			<54905 46057 16845 13340 13313 13313>,
			<54905 46057 16845 13340 13313 13313>,
			<54905 46057 16845 13340 13313 13313>;
	};

	qcom,pc-temp-y4-lut {
		qcom,lut-col-legend = <(-10) 0 10 25 40 50>;
		qcom,lut-row-legend = <10000 9800 9600 9400 9200 9000>,
			<8800 8600 8400 8200 8000 7800>,
			<7600 7400 7200 7000 6800 6600>,
			<6400 6200 6000 5800 5600 5400>,
			<5200 5000 4800 4600 4400 4200>,
			<4000 3800 3600 3400 3200 3000>,
			<2800 2600 2400 2200 2000 1800>,
			<1600 1400 1200 1000 900 800>,
			<700 600 500 400 300 200>,
			<100 0>;
		qcom,lut-data = <16989 16735 16637 16499 16474 16464>,
			<17103 16815 16678 16503 16474 16468>,
			<17219 16930 16734 16507 16475 16472>,
			<17321 17048 16792 16511 16476 16477>,
			<17392 17138 16834 16514 16476 16480>,
			<17416 17167 16848 16516 16477 16481>,
			<17394 17155 16842 16517 16477 16481>,
			<17359 17138 16833 16518 16478 16481>,
			<17337 17130 16826 16520 16480 16481>,
			<17321 17125 16819 16524 16483 16483>,
			<17309 17122 16818 16528 16487 16486>,
			<17303 17120 16825 16533 16490 16490>,
			<17296 17120 16837 16539 16495 16494>,
			<17276 17137 16857 16547 16501 16498>,
			<17232 17173 16883 16557 16509 16502>,
			<17176 17175 16899 16571 16517 16507>,
			<17085 17119 16910 16596 16525 16511>,
			<16997 17047 16914 16622 16536 16519>,
			<16950 16978 16861 16649 16568 16545>,
			<16917 16908 16778 16671 16601 16572>,
			<16878 16860 16730 16655 16591 16566>,
			<16829 16826 16694 16578 16543 16534>,
			<16787 16788 16667 16528 16508 16508>,
			<16760 16736 16647 16510 16488 16489>,
			<16740 16689 16633 16500 16477 16477>,
			<16737 16670 16623 16500 16478 16477>,
			<16745 16658 16616 16503 16481 16478>,
			<16751 16655 16602 16507 16486 16481>,
			<16755 16656 16571 16512 16496 16492>,
			<16759 16658 16547 16518 16508 16504>,
			<16760 16665 16539 16525 16520 16516>,
			<16764 16678 16533 16532 16531 16526>,
			<16768 16689 16537 16537 16534 16532>,
			<16769 16698 16558 16542 16536 16535>,
			<16771 16706 16582 16544 16536 16536>,
			<16771 16714 16609 16537 16530 16528>,
			<16771 16721 16635 16525 16518 16516>,
			<16771 16726 16657 16519 16509 16508>,
			<16769 16729 16677 16515 16499 16501>,
			<16766 16731 16685 16514 16496 16500>,
			<16769 16728 16688 16520 16501 16507>,
			<16779 16723 16687 16523 16501 16507>,
			<16787 16701 16676 16519 16487 16492>,
			<16798 16686 16662 16512 16475 16469>,
			<16794 16659 16634 16490 16466 16462>,
			<16776 16670 16653 16506 16490 16504>,
			<16789 16685 16672 16523 16522 16542>,
			<16800 16705 16701 16549 16557 16578>,
			<16818 16736 16744 16583 16591 16606>,
			<16838 16775 16789 16610 16596 16598>,
			<16928 16776 16804 16555 16507 16509>,
			<17326 16894 16794 16540 16494 16502>,
			<19286 18534 16798 16563 16502 16503>,
			<43868 43603 17467 16608 16519 16515>,
			<43868 43603 17467 16608 16519 16515>,
			<43868 43603 17467 16608 16519 16515>;
	};

	qcom,pc-temp-y5-lut {
		qcom,lut-col-legend = <(-10) 0 10 25 40 50>;
		qcom,lut-row-legend = <10000 9800 9600 9400 9200 9000>,
			<8800 8600 8400 8200 8000 7800>,
			<7600 7400 7200 7000 6800 6600>,
			<6400 6200 6000 5800 5600 5400>,
			<5200 5000 4800 4600 4400 4200>,
			<4000 3800 3600 3400 3200 3000>,
			<2800 2600 2400 2200 2000 1800>,
			<1600 1400 1200 1000 900 800>,
			<700 600 500 400 300 200>,
			<100 0>;
		qcom,lut-data = <12016 13294 15884 19192 13317 22283>,
			<12489 13763 15881 18962 14914 21756>,
			<12951 14220 15931 18655 16693 20994>,
			<13401 14664 16025 18315 18325 20197>,
			<13837 15094 16153 17984 19477 19564>,
			<14261 15512 16309 17707 19823 19289>,
			<14738 16015 16567 17457 19571 19244>,
			<15136 16381 16770 17182 19112 19204>,
			<15282 16361 16758 16818 18498 18947>,
			<15360 16223 16670 16351 17655 18330>,
			<15433 16151 16537 15961 17045 17642>,
			<15499 16132 16181 15630 16653 16757>,
			<15599 16136 15895 15380 16269 16053>,
			<16453 16434 15847 15240 15667 15713>,
			<18601 17273 15846 15119 15063 15489>,
			<19343 18473 16272 14893 14978 15528>,
			<17616 20723 18383 14357 15117 15909>,
			<15916 22068 19972 14044 15198 16126>,
			<15929 21786 20468 15457 15132 15656>,
			<16157 21132 20792 17926 15047 15060>,
			<16210 20193 21034 19532 15925 15681>,
			<15931 18646 21218 20852 18884 18004>,
			<15461 17944 21390 21310 20114 19403>,
			<14563 18355 21632 21031 19989 19973>,
			<13336 18842 21919 20663 19770 20257>,
			<12851 17660 22386 20508 19347 19966>,
			<12664 14015 23110 20388 18561 19096>,
			<12570 12632 23718 20188 17740 18033>,
			<12639 12859 24447 19683 16601 16342>,
			<12810 13095 24849 19315 15948 15370>,
			<12934 13141 22691 19578 16543 15443>,
			<13156 13163 19121 20289 17640 15643>,
			<13362 13236 17815 21215 18203 16202>,
			<13540 13501 17224 22706 18487 17744>,
			<13685 13810 16902 23597 18959 19054>,
			<13707 14080 16907 23739 20838 19962>,
			<13708 14334 17024 23816 22698 20591>,
			<13705 14516 16793 23254 22463 20758>,
			<13618 14669 16192 21173 21385 20741>,
			<13448 14724 15921 20232 20999 20734>,
			<13184 14538 15347 20442 21084 20844>,
			<12845 14414 14984 20437 21083 21519>,
			<12912 14468 14664 18953 20700 23376>,
			<13022 13952 14165 18872 17681 18948>,
			<13065 13635 14174 18797 17132 17985>,
			<13244 13412 14330 18486 18260 17269>,
			<13263 13469 14484 18560 17747 16496>,
			<13519 13658 14442 19260 17295 16269>,
			<13659 13802 14225 18964 17233 16117>,
			<13747 13924 14548 19206 17384 15960>,
			<13228 13791 14632 19057 17783 16043>,
			<11417 12293 14012 18959 17804 15969>,
			<9701 9921 13510 19867 17767 16352>,
			<8939 8920 11327 21265 21579 21647>,
			<8939 8920 11327 21265 21579 21647>,
			<8939 8920 11327 21265 21579 21647>;
	};

	qcom,pc-temp-y6-lut {
		qcom,lut-col-legend = <(-10) 0 10 25 40 50>;
		qcom,lut-row-legend = <10000 9800 9600 9400 9200 9000>,
			<8800 8600 8400 8200 8000 7800>,
			<7600 7400 7200 7000 6800 6600>,
			<6400 6200 6000 5800 5600 5400>,
			<5200 5000 4800 4600 4400 4200>,
			<4000 3800 3600 3400 3200 3000>,
			<2800 2600 2400 2200 2000 1800>,
			<1600 1400 1200 1000 900 800>,
			<700 600 500 400 300 200>,
			<100 0>;
		qcom,lut-data = <6415 5719 5372 5121 5065 5059>,
			<6387 5756 5391 5123 5068 5061>,
			<6358 5782 5404 5125 5071 5063>,
			<6329 5798 5412 5127 5074 5065>,
			<6299 5806 5416 5128 5076 5066>,
			<6269 5808 5417 5129 5078 5068>,
			<6236 5800 5412 5130 5079 5069>,
			<6205 5786 5405 5130 5079 5070>,
			<6176 5774 5399 5131 5080 5071>,
			<6149 5761 5393 5132 5081 5071>,
			<6125 5750 5389 5133 5082 5072>,
			<6104 5738 5385 5134 5084 5073>,
			<6086 5731 5383 5136 5086 5075>,
			<6072 5731 5384 5139 5088 5076>,
			<6062 5732 5385 5142 5090 5078>,
			<6045 5730 5386 5146 5093 5081>,
			<6007 5717 5389 5152 5097 5084>,
			<5971 5699 5390 5157 5101 5088>,
			<5956 5677 5371 5166 5109 5095>,
			<5947 5652 5341 5173 5116 5101>,
			<5939 5633 5324 5167 5112 5097>,
			<5929 5616 5311 5141 5094 5083>,
			<5923 5604 5303 5124 5082 5072>,
			<5922 5597 5297 5117 5075 5066>,
			<5922 5593 5294 5114 5071 5063>,
			<5924 5593 5294 5114 5071 5063>,
			<5942 5595 5294 5115 5072 5063>,
			<5966 5600 5293 5117 5073 5064>,
			<5990 5625 5290 5118 5075 5066>,
			<6017 5659 5287 5120 5078 5068>,
			<6045 5693 5289 5123 5082 5071>,
			<6075 5730 5294 5126 5087 5075>,
			<6104 5769 5303 5129 5088 5077>,
			<6132 5812 5324 5132 5089 5080>,
			<6160 5856 5348 5134 5089 5081>,
			<6186 5898 5378 5133 5087 5078>,
			<6211 5940 5411 5131 5085 5074>,
			<6234 5977 5444 5130 5083 5072>,
			<6256 6012 5479 5130 5080 5071>,
			<6277 6042 5513 5130 5079 5071>,
			<6296 6069 5546 5136 5082 5074>,
			<6316 6094 5580 5139 5082 5075>,
			<6343 6117 5615 5138 5077 5069>,
			<6382 6143 5648 5138 5071 5061>,
			<6423 6147 5648 5131 5071 5061>,
			<6477 6223 5745 5144 5085 5080>,
			<6539 6275 5813 5152 5097 5093>,
			<6625 6339 5898 5165 5109 5105>,
			<6746 6425 6002 5177 5119 5113>,
			<6955 6555 6146 5187 5120 5110>,
			<7610 6803 6278 5169 5092 5081>,
			<9650 7809 6426 5170 5089 5081>,
			<15989 12248 6766 5194 5096 5087>,
			<40664 36206 8508 5234 5111 5102>,
			<40664 36206 8508 5234 5111 5102>,
			<40664 36206 8508 5234 5111 5102>;
	};

};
